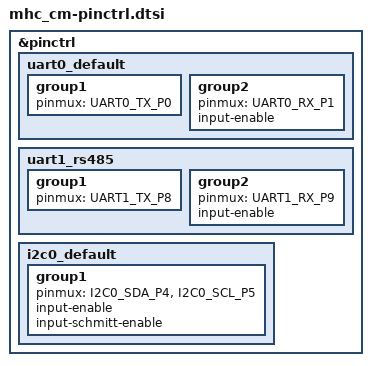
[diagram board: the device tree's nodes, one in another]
/*
 * Copyright (c) 2026 MASSDRIVER EI (massdriver.space)
 * SPDX-License-Identifier: Apache-2.0
 */

#include <zephyr/dt-bindings/pinctrl/rpi-pico-rp2350b-pinctrl.h>

&pinctrl {
	uart0_default: uart0_default {
		group1 {
			pinmux = <UART0_TX_P0>;
		};

		group2 {
			pinmux = <UART0_RX_P1>;
			input-enable;
		};
	};

	uart1_rs485: uart1_rs485 {
		group1 {
			pinmux = <UART1_TX_P8>;
		};

		group2 {
			pinmux = <UART1_RX_P9>;
			input-enable;
		};
	};

	i2c0_default: i2c0_default {
		group1 {
			pinmux = <I2C0_SDA_P4>, <I2C0_SCL_P5>;
			input-enable;
			input-schmitt-enable;
		};
	};
};
